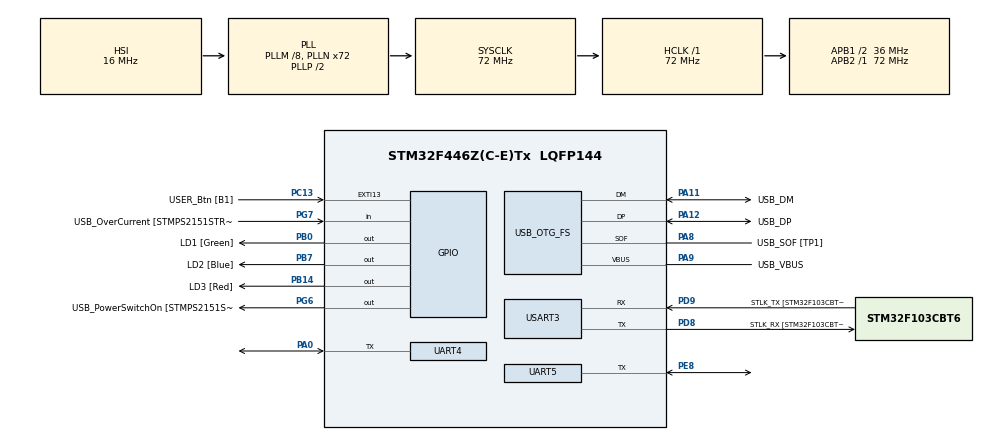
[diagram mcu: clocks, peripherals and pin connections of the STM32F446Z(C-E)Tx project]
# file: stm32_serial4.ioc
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FREERTOS.Tasks01=defaultTask,24,128,StartDefaultTask,Default,NULL,Dynamic,NULL,NULL
Mcu.Family=STM32F4
Mcu.Name=STM32F446Z(C-E)Tx
Mcu.Package=LQFP144
NVIC.OTG_FS_IRQn=true\:5\:0\:false\:false\:true\:true\:false\:true
NVIC.PriorityGroup=NVIC_PRIORITYGROUP_4
NVIC.TIM1_UP_TIM10_IRQn=true\:0\:0\:false\:false\:true\:false\:false\:true
NVIC.TimeBase=TIM1_UP_TIM10_IRQn
NVIC.TimeBaseIP=TIM1
PA0-WKUP.Mode=Half_duplex(single_wire_mode)
PA0-WKUP.Signal=UART4_TX
PA10.GPIO_Label=USB_ID
PA10.Signal=USB_OTG_FS_ID
PA11.GPIO_Label=USB_DM
PA11.Mode=Device_Only
PA11.Signal=USB_OTG_FS_DM
PA12.GPIO_Label=USB_DP
PA12.Mode=Device_Only
PA12.Signal=USB_OTG_FS_DP
PA13.GPIO_Label=TMS
PA13.Mode=Serial_Wire
PA13.Signal=SYS_JTMS-SWDIO
PA14.GPIO_Label=TCK
PA14.Mode=Serial_Wire
PA14.Signal=SYS_JTCK-SWCLK
PA8.GPIO_Label=USB_SOF [TP1]
PA8.Mode=Activate_SOF_FS
PA8.Signal=USB_OTG_FS_SOF
PA9.GPIO_Label=USB_VBUS
PA9.Mode=Activate_VBUS
PA9.Signal=USB_OTG_FS_VBUS
PB0.GPIO_Label=LD1 [Green]
PB0.Signal=GPIO_Output
PB14.GPIO_Label=LD3 [Red]
PB14.Signal=GPIO_Output
PB7.GPIO_Label=LD2 [Blue]
PB7.Signal=GPIO_Output
PC13.GPIO_Label=USER_Btn [B1]
PC13.Signal=GPXTI13
PC14-OSC32_IN.Mode=LSE-External-Oscillator
PC14-OSC32_IN.Signal=RCC_OSC32_IN
PC15-OSC32_OUT.Mode=LSE-External-Oscillator
PC15-OSC32_OUT.Signal=RCC_OSC32_OUT
PD8.GPIO_Label=STLK_RX [STM32F103CBT6_PA3]
PD8.Mode=Asynchronous
PD8.Signal=USART3_TX
PD9.GPIO_Label=STLK_TX [STM32F103CBT6_PA2]
PD9.Mode=Asynchronous
PD9.Signal=USART3_RX
PE8.Mode=Half_duplex(single_wire_mode)
PE8.Signal=UART5_TX
PG6.GPIO_Label=USB_PowerSwitchOn [STMPS2151STR_EN]
PG6.Signal=GPIO_Output
PG7.GPIO_Label=USB_OverCurrent [STMPS2151STR_FAULT]
PG7.Signal=GPIO_Input
PH0-OSC_IN.GPIO_Label=MCO [STM32F103CBT6_PA8]
PH0-OSC_IN.Signal=RCC_OSC_IN
PH1-OSC_OUT.Signal=RCC_OSC_OUT
ProjectManager.HeapSize=0x200
ProjectManager.StackSize=0x400
ProjectManager.TargetToolchain=Other Toolchains (GPDSC)
RCC.48MHZClocksFreq_Value=24000000
RCC.AHBFreq_Value=72000000
RCC.APB1CLKDivider=RCC_HCLK_DIV2
RCC.APB1Freq_Value=36000000
RCC.APB1TimFreq_Value=72000000
RCC.APB2Freq_Value=72000000
RCC.APB2TimFreq_Value=72000000
RCC.CortexFreq_Value=72000000
RCC.HCLKFreq_Value=72000000
RCC.HSE_VALUE=8000000
RCC.HSI_VALUE=16000000
RCC.PLLM=8
RCC.PLLMUL=RCC_PLL_MUL9
RCC.PLLN=72
RCC.PLLQ=3
RCC.PLLSourceVirtualString=RCC_PLLSOURCE_HSI
RCC.PRESCALERUSB=RCC_USBCLKSOURCE_PLL_DIV1_5
RCC.RCC_RTC_Clock_SourceVirtual=RCC_RTCCLKSOURCE_LSE
RCC.SYSCLKFreq_VALUE=72000000
RCC.SYSCLKSource=RCC_SYSCLKSOURCE_PLLCLK
RCC.SYSCLKSourceVirtual=RCC_SYSCLKSOURCE_PLLCLK
RCC.USBFreq_Value=48000000
RCC.VCOOutputFreq_Value=144000000
UART4.BaudRate=2000000
UART4.VirtualMode=Asynchronous
UART5.BaudRate=2000000
UART5.VirtualMode=Asynchronous
USART3.VirtualMode=VM_ASYNC
USB_DEVICE.CLASS_NAME_FS=CDC
USB_DEVICE.VirtualMode-CDC_FS=Cdc
USB_DEVICE.VirtualModeFS=Cdc_FS
USB_OTG_FS.VirtualMode=Device_Only
VP_FREERTOS_VS_CMSIS_V2.Mode=CMSIS_V2
VP_RTC_VS_RTC_Activate.Mode=RTC_Enabled
VP_RTC_VS_RTC_Calendar.Mode=RTC_Calendar
VP_SYS_VS_tim1.Mode=TIM1
VP_USB_DEVICE_VS_USB_DEVICE_CDC_FS.Mode=CDC_FS
board=NUCLEO-F446ZE

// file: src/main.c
/* USER CODE BEGIN Header */
/**
  ******************************************************************************
  * @file           : main.c
  * @brief          : Main program body
  ******************************************************************************
  * @attention
  *
  * <h2><center>&copy; Copyright (c) 2020 STMicroelectronics.
  * All rights reserved.</center></h2>
  *
  * This software component is licensed by ST under Ultimate Liberty license
  * SLA0044, the "License"; You may not use this file except in compliance with
  * the License. You may obtain a copy of the License at:
  *                             www.st.com/SLA0044
  *
  ******************************************************************************
  */
/* USER CODE END Header */

#include "main.h"
//#include "cmsis_os.h"
#include "rtc.h"
#include "usart.h"
#include "usb_device.h"
#include "gpio.h"

#include "FreeRTOS.h"
#include "task.h"
#include "timers.h"
#include "queue.h"
#include "semphr.h"
#include "event_groups.h"

void SystemClock_Config(void);
void MX_FREERTOS_Init(void);

int main(void)
{

  /* MCU Configuration--------------------------------------------------------*/

  /* Reset of all peripherals, Initializes the Flash interface and the Systick. */
  HAL_Init();

  /* Configure the system clock */
  SystemClock_Config();

  /* Initialize all configured peripherals */
  MX_GPIO_Init();
  MX_RTC_Init();
  MX_UART4_Init();
  MX_UART5_Init();
  MX_USART3_UART_Init();

  /* Init scheduler */
  /* Call init function for freertos objects (in freertos.c) */
  //osKernelInitialize();
  MX_FREERTOS_Init();
  /* Start scheduler */
  //osKernelStart();
  vTaskStartScheduler();

  /* We should never get here as control is now taken by the scheduler */
  /* Infinite loop */
  while (1)
  {

  }
}

void SystemClock_Config(void)
{
  RCC_OscInitTypeDef RCC_OscInitStruct = {0};
  RCC_ClkInitTypeDef RCC_ClkInitStruct = {0};
  RCC_PeriphCLKInitTypeDef PeriphClkInitStruct = {0};

  /** Configure the main internal regulator output voltage
  */
  __HAL_RCC_PWR_CLK_ENABLE();
  __HAL_PWR_VOLTAGESCALING_CONFIG(PWR_REGULATOR_VOLTAGE_SCALE3);
  /** Initializes the CPU, AHB and APB busses clocks
  */
  RCC_OscInitStruct.OscillatorType = RCC_OSCILLATORTYPE_HSI|RCC_OSCILLATORTYPE_LSE;
  RCC_OscInitStruct.LSEState = RCC_LSE_ON;
  RCC_OscInitStruct.HSIState = RCC_HSI_ON;
  RCC_OscInitStruct.HSICalibrationValue = RCC_HSICALIBRATION_DEFAULT;
  RCC_OscInitStruct.PLL.PLLState = RCC_PLL_ON;
  RCC_OscInitStruct.PLL.PLLSource = RCC_PLLSOURCE_HSI;
  RCC_OscInitStruct.PLL.PLLM = 8;
  RCC_OscInitStruct.PLL.PLLN = 72;
  RCC_OscInitStruct.PLL.PLLP = RCC_PLLP_DIV2;
  RCC_OscInitStruct.PLL.PLLQ = 3;
  RCC_OscInitStruct.PLL.PLLR = 2;
  if (HAL_RCC_OscConfig(&RCC_OscInitStruct) != HAL_OK)
  {
    Error_Handler();
  }
  /** Initializes the CPU, AHB and APB busses clocks
  */
  RCC_ClkInitStruct.ClockType = RCC_CLOCKTYPE_HCLK|RCC_CLOCKTYPE_SYSCLK
                              |RCC_CLOCKTYPE_PCLK1|RCC_CLOCKTYPE_PCLK2;
  RCC_ClkInitStruct.SYSCLKSource = RCC_SYSCLKSOURCE_PLLCLK;
  RCC_ClkInitStruct.AHBCLKDivider = RCC_SYSCLK_DIV1;
  RCC_ClkInitStruct.APB1CLKDivider = RCC_HCLK_DIV2;
  RCC_ClkInitStruct.APB2CLKDivider = RCC_HCLK_DIV1;

  if (HAL_RCC_ClockConfig(&RCC_ClkInitStruct, FLASH_LATENCY_2) != HAL_OK)
  {
    Error_Handler();
  }
  PeriphClkInitStruct.PeriphClockSelection = RCC_PERIPHCLK_RTC|RCC_PERIPHCLK_CLK48;
  PeriphClkInitStruct.RTCClockSelection = RCC_RTCCLKSOURCE_LSE;
  PeriphClkInitStruct.Clk48ClockSelection = RCC_CLK48CLKSOURCE_PLLQ;
  if (HAL_RCCEx_PeriphCLKConfig(&PeriphClkInitStruct) != HAL_OK)
  {
    Error_Handler();
  }
}

 /**
  * @brief  Period elapsed callback in non blocking mode
  * @note   This function is called  when TIM1 interrupt took place, inside
  * HAL_TIM_IRQHandler(). It makes a direct call to HAL_IncTick() to increment
  * a global variable "uwTick" used as application time base.
  * @param  htim : TIM handle
  * @retval None
  */
void HAL_TIM_PeriodElapsedCallback(TIM_HandleTypeDef *htim)
{
  if (htim->Instance == TIM1) {
    HAL_IncTick();
  }
}

void Error_Handler(void)
{
}

/************************ (C) COPYRIGHT STMicroelectronics *****END OF FILE****/

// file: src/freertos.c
/* USER CODE BEGIN Header */
/**
  ******************************************************************************
  * File Name          : freertos.c
  * Description        : Code for freertos applications
  ******************************************************************************
  * @attention
  *
  * <h2><center>&copy; Copyright (c) 2020 STMicroelectronics.
  * All rights reserved.</center></h2>
  *
  * This software component is licensed by ST under Ultimate Liberty license
  * SLA0044, the "License"; You may not use this file except in compliance with
  * the License. You may obtain a copy of the License at:
  *                             www.st.com/SLA0044
  *
  ******************************************************************************
  */
/* USER CODE END Header */

// #include "FreeRTOS.h"
// #include "task.h"
// #include "main.h"
// #include "cmsis_os.h"

#include "FreeRTOS.h"
#include "task.h"
#include "timers.h"
#include "queue.h"
#include "semphr.h"
#include "event_groups.h"

#include "main.h"

/* Definitions for defaultTask */
// osThreadId defaultTaskHandle;
// const osThreadAttr_t defaultTask_attributes = {
//   .name = "defaultTask",
//   .priority = (osPriority) osPriorityNormal,
//   .stack_size = 128 * 4
// };

void StartDefaultTask(void *argument);

extern void MX_USB_DEVICE_Init(void);
void MX_FREERTOS_Init(void); /* (MISRA C 2004 rule 8.1) */

void MX_FREERTOS_Init(void) {

  /* Create the thread(s) */
  /* creation of defaultTask */

  //defaultTaskHandle = osThreadNew(StartDefaultTask, NULL, &defaultTask_attributes);

  xTaskCreate( StartDefaultTask,
            "StartDefaultTask",
            1024/4,
            NULL,
            tskIDLE_PRIORITY+1,
            NULL );

}

#include "usart.h"
#include "usbd_cdc_if.h"

void StartDefaultTask(void *argument)
{
  /* init code for USB_DEVICE */
  MX_USB_DEVICE_Init();
  /* USER CODE BEGIN StartDefaultTask */
  /* Infinite loop */
  for(;;)
  {
    //osDelay(1);
    vTaskDelay(500);
    uint8_t hewo[]= "Hello world!\r\n";
    HAL_UART_Transmit(&huart3,hewo,sizeof(hewo)-1,10000);
    CDC_Transmit_FS((uint8_t*)"Hello usb world!\r\n",18);
  }
  /* USER CODE END StartDefaultTask */
}

/************************ (C) COPYRIGHT STMicroelectronics *****END OF FILE****/
